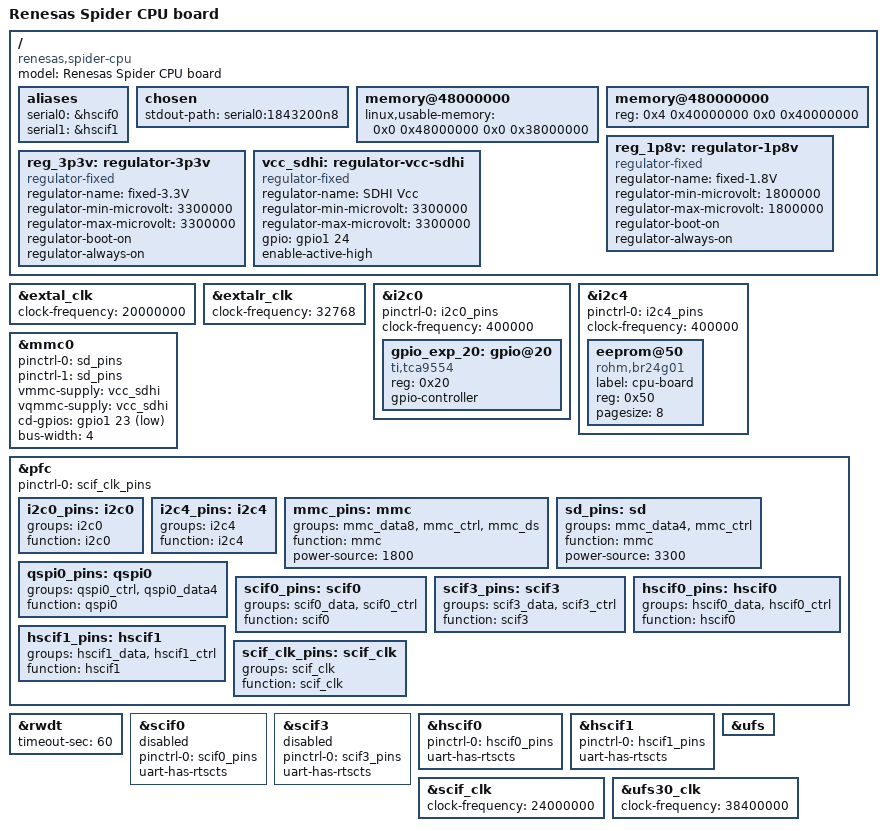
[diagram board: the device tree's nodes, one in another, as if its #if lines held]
// SPDX-License-Identifier: GPL-2.0
/*
 * Device Tree Source for the Spider CPU board
 *
 * Copyright (C) 2021 Renesas Electronics Corp.
 */

#include <dt-bindings/gpio/gpio.h>
#include "r8a779f0.dtsi"

/ {
	model = "Renesas Spider CPU board";
	compatible = "renesas,spider-cpu", "renesas,r8a779f0";

	aliases {
		serial0 = &hscif0;
		serial1 = &hscif1;
	};

	chosen {
		stdout-path = "serial0:1843200n8";
	};

	memory@48000000 {
		device_type = "memory";
		/* first 128MB is reserved for secure area. */
		linux,usable-memory = <0x0 0x48000000 0x0 0x38000000>;
	};

	memory@480000000 {
		device_type = "memory";
		reg = <0x4 0x40000000 0x0 0x40000000>;
	};

	reg_1p8v: regulator-1p8v {
		compatible = "regulator-fixed";
		regulator-name = "fixed-1.8V";
		regulator-min-microvolt = <1800000>;
		regulator-max-microvolt = <1800000>;
		regulator-boot-on;
		regulator-always-on;
	};

	reg_3p3v: regulator-3p3v {
		compatible = "regulator-fixed";
		regulator-name = "fixed-3.3V";
		regulator-min-microvolt = <3300000>;
		regulator-max-microvolt = <3300000>;
		regulator-boot-on;
		regulator-always-on;
	};

	vcc_sdhi: regulator-vcc-sdhi {
		compatible = "regulator-fixed";

		regulator-name = "SDHI Vcc";
		regulator-min-microvolt = <3300000>;
		regulator-max-microvolt = <3300000>;

		gpio = <&gpio1 24 GPIO_ACTIVE_HIGH>;
		enable-active-high;
	};
};

&extal_clk {
	clock-frequency = <20000000>;
};

&extalr_clk {
	clock-frequency = <32768>;
};

&i2c0 {
	pinctrl-0 = <&i2c0_pins>;
	pinctrl-names = "default";

	status = "okay";
	clock-frequency = <400000>;

	gpio_exp_20: gpio@20 {
		compatible = "ti,tca9554";
		reg = <0x20>;
		gpio-controller;
		#gpio-cells = <2>;
	};
};

&i2c4 {
	pinctrl-0 = <&i2c4_pins>;
	pinctrl-names = "default";

	status = "okay";
	clock-frequency = <400000>;

	eeprom@50 {
		compatible = "rohm,br24g01", "atmel,24c01";
		label = "cpu-board";
		reg = <0x50>;
		pagesize = <8>;
	};
};

#ifdef S4_USE_SD
&mmc0 {
	pinctrl-0 = <&sd_pins>;
	pinctrl-1 = <&sd_pins>;
	pinctrl-names = "default", "state_uhs";

	vmmc-supply = <&vcc_sdhi>;
	vqmmc-supply = <&vcc_sdhi>;
	cd-gpios = <&gpio1 23 GPIO_ACTIVE_LOW>;
	bus-width = <4>;
	status = "okay";
};
#else
&mmc0 {
	pinctrl-0 = <&mmc_pins>;
	pinctrl-1 = <&mmc_pins>;
	pinctrl-names = "default", "state_uhs";

	vmmc-supply = <&reg_3p3v>;
	vqmmc-supply = <&reg_1p8v>;
	mmc-hs200-1_8v;
	mmc-hs400-1_8v;
	bus-width = <8>;
	no-sd;
	no-sdio;
	non-removable;
	full-pwr-cycle-in-suspend;
	status = "okay";
};
#endif

&pfc {
	pinctrl-0 = <&scif_clk_pins>;
	pinctrl-names = "default";

	i2c0_pins: i2c0 {
		groups = "i2c0";
		function = "i2c0";
	};

	i2c4_pins: i2c4 {
		groups = "i2c4";
		function = "i2c4";
	};

	mmc_pins: mmc {
		groups = "mmc_data8", "mmc_ctrl", "mmc_ds";
		function = "mmc";
		power-source = <1800>;
	};

	sd_pins: sd {
		groups = "mmc_data4", "mmc_ctrl";
		function = "mmc";
		power-source = <3300>;
	};

	qspi0_pins: qspi0 {
		groups = "qspi0_ctrl", "qspi0_data4";
		function = "qspi0";
	};

	scif0_pins: scif0 {
		groups = "scif0_data", "scif0_ctrl";
		function = "scif0";
	};

	scif3_pins: scif3 {
		groups = "scif3_data", "scif3_ctrl";
		function = "scif3";
	};

	hscif0_pins: hscif0 {
		groups = "hscif0_data", "hscif0_ctrl";
		function = "hscif0";
	};

	hscif1_pins: hscif1 {
		groups = "hscif1_data", "hscif1_ctrl";
		function = "hscif1";
	};

	scif_clk_pins: scif_clk {
		groups = "scif_clk";
		function = "scif_clk";
	};
};

&rwdt {
	timeout-sec = <60>;
	status = "okay";
};

&scif0 {
	pinctrl-0 = <&scif0_pins>;
	pinctrl-names = "default";

	uart-has-rtscts;
	/* Please use exclusively to the hscif1 node */
	status = "disabled";
};

&scif3 {
	pinctrl-0 = <&scif3_pins>;
	pinctrl-names = "default";

	uart-has-rtscts;
	/* Please use exclusively to the hscif0 node */
	status = "disabled";
};

&hscif0 {
	pinctrl-0 = <&hscif0_pins>;
	pinctrl-names = "default";

	uart-has-rtscts;
	/* Please use exclusively to the scif3 node */
	status = "okay";
};

&hscif1 {
	pinctrl-0 = <&hscif1_pins>;
	pinctrl-names = "default";

	uart-has-rtscts;
	/* Please use exclusively to the scif0 node */
	status = "okay";
};

&scif_clk {
	clock-frequency = <24000000>;
};

&ufs {
	status = "okay";
};

&ufs30_clk {
	clock-frequency = <38400000>;
};
